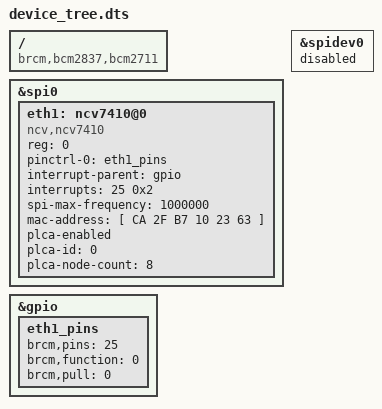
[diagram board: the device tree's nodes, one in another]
/dts-v1/;
/plugin/;

/ {
        compatible = "brcm,bcm2837,bcm2711";

        fragment@0 {
                target = <&spi0>;
                __overlay__ {
					   #address-cells = <1>;
                       #size-cells = <0>;
                       status = "okay";
					   eth1: ncv7410@0{
								#address-cells = <1>;
								#size-cells = <0>;
                                compatible = "ncv,ncv7410";
                                reg = <0>; /* CE0 */
                                pinctrl-names = "default";
                                pinctrl-0 = <&eth1_pins>;
                                interrupt-parent = <&gpio>;
                                interrupts = <25 0x2>; 
                                spi-max-frequency = <1000000>;
                                mac-address = [ CA 2F B7 10 23 63 ];
								plca-enabled;
                                plca-id = <0>;
								plca-node-count = <8>;
								status = "okay";
                        };
                };
        };

        fragment@1 {
                target = <&spidev0>;
                __overlay__ {
                        status = "disabled";
                };
        };

        fragment@2 {
                target = <&gpio>;
                __overlay__ {
                        eth1_pins: eth1_pins {
                                brcm,pins = <25>;
                                brcm,function = <0>; /* in */
                                brcm,pull = <0>; /* none */
                        };
                };
        };
};
